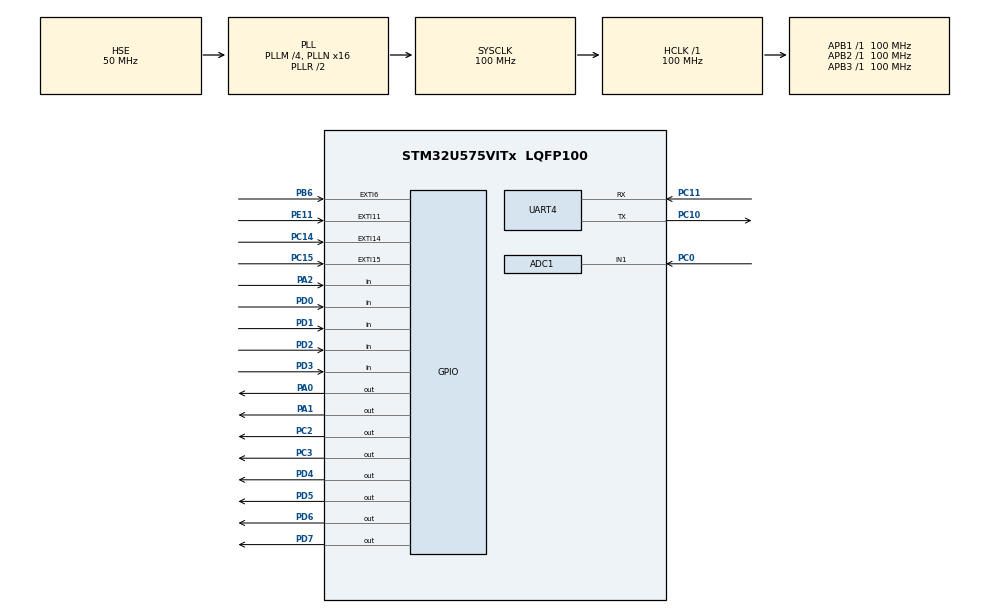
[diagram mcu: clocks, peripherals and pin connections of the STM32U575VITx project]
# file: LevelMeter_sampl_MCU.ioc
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ADC1.Channel-0\#ChannelRegularConversion=ADC_CHANNEL_1
ADC1.ContinuousConvMode=DISABLE
ADC1.ConversionDataManagement=ADC_CONVERSIONDATA_DMA_ONESHOT
ADC1.DiscontinuousConvMode=ENABLE
ADC1.EnableInjectedConversion=DISABLE
ADC1.EnableRegularConversion=ENABLE
ADC1.ExternalTrigConv=ADC_EXTERNALTRIG_EXT_IT15
ADC1.MonitoredBy-0\#ChannelRegularConversion=__NULL
ADC1.NbrOfConversion=1
ADC1.NbrOfConversionFlag=1
ADC1.OffsetNumber-0\#ChannelRegularConversion=ADC_OFFSET_NONE
ADC1.Overrun=ADC_OVR_DATA_OVERWRITTEN
ADC1.OversamplingMode=DISABLE
ADC1.Rank-0\#ChannelRegularConversion=1
ADC1.SamplingTime-0\#ChannelRegularConversion=ADC_SAMPLETIME_5CYCLE
ADC1.master=1
CORTEX_M33_NS.userName=CORTEX_M33
GPDMA1.CIRCULARMODE_GPDMACH0=DISABLE
GPDMA1.DATAEXCHANGEDESRCBYTE_GPDMACH0=NONE
GPDMA1.DATAEXCHANGEDESTHALFWORD_GPDMACH0=NONE
GPDMA1.DATAEXCHANGE_GPDMACH0-SIMPLEREQUEST_GPDMACH0=DMA_EXCHANGE_DEST_HALFWORD
GPDMA1.DATAHANDLING_GPDMACH0=NONE
GPDMA1.DESTBURSTLENGTH_GPDMACH0=1
GPDMA1.DESTDATAWIDTH_GPDMACH0=DMA_DEST_DATAWIDTH_HALFWORD
GPDMA1.DESTINC_GPDMACH0=DMA_DINC_INCREMENTED
GPDMA1.IPHANDLE_GPDMACH0-SIMPLEREQUEST_GPDMACH0=__NULL
GPDMA1.LINKALLOCATEDPORT_CIRCULAR_GPDMACH0=DMA_LINK_ALLOCATED_PORT0
GPDMA1.REQUEST_GPDMACH0=GPDMA1_REQUEST_ADC1
GPDMA1.SRCBURSTLENGTH_GPDMACH0=1
GPDMA1.SRCDATAWIDTH_GPDMACH0=DMA_SRC_DATAWIDTH_HALFWORD
GPDMA1.TRIGGERPOLARITY_GPDMACH0=DMA_TRIG_POLARITY_MASKED
Mcu.Family=STM32U5
Mcu.Name=STM32U575VITx
Mcu.Package=LQFP100
NVIC.ADC1_IRQn=true\:0\:0\:false\:false\:true\:true\:true\:true
NVIC.EXTI6_IRQn=true\:0\:0\:false\:false\:true\:true\:true\:true
NVIC.GPDMA1_Channel0_IRQn=true\:0\:0\:false\:false\:true\:false\:true\:true
NVIC.PriorityGroup=NVIC_PRIORITYGROUP_4
NVIC.TIM6_IRQn=true\:0\:0\:false\:false\:true\:true\:true\:true
NVIC.UART4_IRQn=true\:0\:0\:false\:false\:true\:true\:true\:true
PA0.Signal=GPIO_Output
PA1.Signal=GPIO_Output
PA2.Signal=GPIO_Input
PB6.Signal=GPXTI6
PC0.Mode=IN1-Single-Ended
PC0.Signal=ADC1_IN1
PC10.Mode=Asynchronous
PC10.Signal=UART4_TX
PC11.Mode=Asynchronous
PC11.Signal=UART4_RX
PC14-OSC32_IN\ (PC14).Signal=GPXTI14
PC15-OSC32_OUT\ (PC15).Signal=GPXTI15
PC2.Signal=GPIO_Output
PC3.Signal=GPIO_Output
PD0.Signal=GPIO_Input
PD1.Signal=GPIO_Input
PD2.Signal=GPIO_Input
PD3.Signal=GPIO_Input
PD4.Signal=GPIO_Output
PD5.Signal=GPIO_Output
PD6.Signal=GPIO_Output
PD7.Signal=GPIO_Output
PE11.Signal=GPXTI11
PH0-OSC_IN\ (PH0).Mode=HSE-DIG-External-Clock-Source
PH0-OSC_IN\ (PH0).Signal=RCC_OSC_IN
ProjectManager.HeapSize=0x200
ProjectManager.StackSize=0x400
ProjectManager.TargetToolchain=STM32CubeIDE
RCC.ADCCLockSelection=RCC_ADCDACCLKSOURCE_HSE
RCC.ADCFreq_Value=50000000
RCC.AHBFreq_Value=100000000
RCC.APB1Freq_Value=100000000
RCC.APB1TimFreq_Value=100000000
RCC.APB2Freq_Value=100000000
RCC.APB2TimFreq_Value=100000000
RCC.APB3Freq_Value=100000000
RCC.CortexFreq_Value=100000000
RCC.EPOD_VALUE=50000000
RCC.HCLKFreq_Value=100000000
RCC.HSE_VALUE=50000000
RCC.HSI48_VALUE=48000000
RCC.HSI_VALUE=16000000
RCC.LSE_VALUE=32768
RCC.LSIDIV_VALUE=32000
RCC.MSIClockRange=RCC_MSIRANGE_0
RCC.MSIKClockRange=RCC_MSIKRANGE_0
RCC.MSI_VALUE=48000000
RCC.PLL1Q=4
RCC.PLL2M=4
RCC.PLL2N=16
RCC.PLL2Q=4
RCC.PLL2R=4
RCC.PLL2Source=RCC_PLLSOURCE_HSE
RCC.PLL3Source=RCC_PLLSOURCE_HSE
RCC.PLLM=4
RCC.PLLN=16
RCC.PLLSourceVirtual=RCC_PLLSOURCE_HSE
RCC.SYSCLKFreq_VALUE=100000000
RCC.SYSCLKSource=RCC_SYSCLKSOURCE_PLLCLK
RCC.USBFreq_Value=48000000
RCC.VCOOutputFreq_Value=200000000
TIM6.AutoReloadPreload=TIM_AUTORELOAD_PRELOAD_ENABLE
TIM6.Dithering=Disable
TIM6.PeriodNoDither=10000
TIM6.Prescaler=10000
TIM6.TIM_MasterOutputTrigger=TIM_TRGO_RESET
VP_GPDMA1_VS_GPDMACH0.Mode=SIMPLEREQUEST_GPDMACH0
VP_ICACHE_VS_ICACHE.Mode=DirectMappedCache
VP_LPBAMQUEUE_VS_QUEUE.Mode=QUEUEMODE
VP_MEMORYMAP_VS_MEMORYMAP.Mode=CurAppReg
VP_PWR_VS_SECSignals.Mode=Security/Privilege
VP_PWR_Vdda.Mode=isolationVdda
VP_TIM6_VS_ClockSourceINT.Mode=Enable_Timer
board=custom

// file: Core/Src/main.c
/* USER CODE BEGIN Header */
/**
  ******************************************************************************
  * @file           : main.c
  * @brief          : Main program body
  ******************************************************************************
  * @attention
  *
  * Copyright (c) 2025 STMicroelectronics.
  * All rights reserved.
  *
  * This software is licensed under terms that can be found in the LICENSE file
  * in the root directory of this software component.
  * If no LICENSE file comes with this software, it is provided AS-IS.
  *
  ******************************************************************************
  */
/* USER CODE END Header */
#include "main.h"
#include "adc.h"
#include "gpdma.h"
#include "icache.h"
#include "memorymap.h"
#include "tim.h"
#include "usart.h"
#include "gpio.h"

void SystemClock_Config(void);

int main(void)
{

  /* MCU Configuration--------------------------------------------------------*/

  /* Reset of all peripherals, Initializes the Flash interface and the Systick. */
  HAL_Init();

  /* Configure the system clock */
  SystemClock_Config();

  /* Initialize all configured peripherals */
  MX_GPIO_Init();
  MX_GPDMA1_Init();
  MX_ADC1_Init();
  MX_ICACHE_Init();
  MX_TIM6_Init();
  MX_UART4_Init();
  /* USER CODE BEGIN 2 */

  main_init();

  /* USER CODE END 2 */

  /* Infinite loop */
  /* USER CODE BEGIN WHILE */
  while (1)
  {
	  main_cycle();
    /* USER CODE END WHILE */

  }
}

void SystemClock_Config(void)
{
  RCC_OscInitTypeDef RCC_OscInitStruct = {0};
  RCC_ClkInitTypeDef RCC_ClkInitStruct = {0};

  /** Configure the main internal regulator output voltage
  */
  if (HAL_PWREx_ControlVoltageScaling(PWR_REGULATOR_VOLTAGE_SCALE2) != HAL_OK)
  {
    Error_Handler();
  }

  /** Initializes the CPU, AHB and APB buses clocks
  */
  RCC_OscInitStruct.OscillatorType = RCC_OSCILLATORTYPE_HSE;
  RCC_OscInitStruct.HSEState = RCC_HSE_BYPASS_DIGITAL;
  RCC_OscInitStruct.PLL.PLLState = RCC_PLL_ON;
  RCC_OscInitStruct.PLL.PLLSource = RCC_PLLSOURCE_HSE;
  RCC_OscInitStruct.PLL.PLLMBOOST = RCC_PLLMBOOST_DIV4;
  RCC_OscInitStruct.PLL.PLLM = 4;
  RCC_OscInitStruct.PLL.PLLN = 16;
  RCC_OscInitStruct.PLL.PLLP = 2;
  RCC_OscInitStruct.PLL.PLLQ = 4;
  RCC_OscInitStruct.PLL.PLLR = 2;
  RCC_OscInitStruct.PLL.PLLRGE = RCC_PLLVCIRANGE_1;
  RCC_OscInitStruct.PLL.PLLFRACN = 0;
  if (HAL_RCC_OscConfig(&RCC_OscInitStruct) != HAL_OK)
  {
    Error_Handler();
  }

  /** Initializes the CPU, AHB and APB buses clocks
  */
  RCC_ClkInitStruct.ClockType = RCC_CLOCKTYPE_HCLK|RCC_CLOCKTYPE_SYSCLK
                              |RCC_CLOCKTYPE_PCLK1|RCC_CLOCKTYPE_PCLK2
                              |RCC_CLOCKTYPE_PCLK3;
  RCC_ClkInitStruct.SYSCLKSource = RCC_SYSCLKSOURCE_PLLCLK;
  RCC_ClkInitStruct.AHBCLKDivider = RCC_SYSCLK_DIV1;
  RCC_ClkInitStruct.APB1CLKDivider = RCC_HCLK_DIV1;
  RCC_ClkInitStruct.APB2CLKDivider = RCC_HCLK_DIV1;
  RCC_ClkInitStruct.APB3CLKDivider = RCC_HCLK_DIV1;

  if (HAL_RCC_ClockConfig(&RCC_ClkInitStruct, FLASH_LATENCY_3) != HAL_OK)
  {
    Error_Handler();
  }
}

void Error_Handler(void)
{
  __disable_irq();
  while (1)
  {
  }
}
